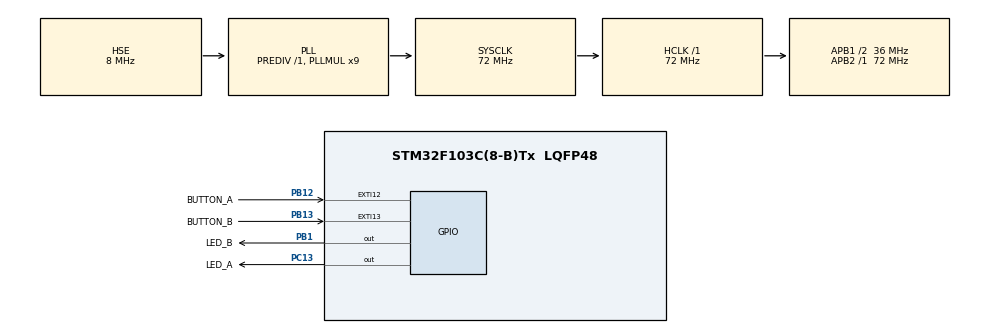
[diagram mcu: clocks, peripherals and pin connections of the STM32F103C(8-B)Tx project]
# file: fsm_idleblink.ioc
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Mcu.Family=STM32F1
RCC.PLLSourceVirtual=RCC_PLLSOURCE_HSE
PC15-OSC32_OUT.Mode=LSE-External-Oscillator
PD1-OSC_OUT.Mode=HSE-External-Oscillator
PC13-TAMPER-RTC.Signal=GPIO_Output
PD0-OSC_IN.Signal=RCC_OSC_IN
RCC.APB1CLKDivider=RCC_HCLK_DIV2
PC14-OSC32_IN.Signal=RCC_OSC32_IN
PB13.GPIO_Label=BUTTON_B
PB13.Signal=GPXTI13
PB13.GPIO_ModeDefaultEXTI=GPIO_MODE_IT_FALLING
RCC.SYSCLKSource=RCC_SYSCLKSOURCE_PLLCLK
ProjectManager.StackSize=0x400
PD1-OSC_OUT.Signal=RCC_OSC_OUT
PA13.Signal=SYS_JTMS-SWDIO
ProjectManager.TargetToolchain=STM32CubeIDE
RCC.HCLKFreq_Value=72000000
RCC.APB2TimFreq_Value=72000000
RCC.USBFreq_Value=72000000
PC15-OSC32_OUT.Signal=RCC_OSC32_OUT
RCC.AHBFreq_Value=72000000
PD0-OSC_IN.Mode=HSE-External-Oscillator
NVIC.EXTI15_10_IRQn=true\:0\:0\:false\:false\:true\:true\:true
board=custom
PC13-TAMPER-RTC.GPIO_Label=LED_A
RCC.PLLMUL=RCC_PLL_MUL9
PB12.GPIO_Label=BUTTON_A
PB13.GPIO_PuPd=GPIO_PULLUP
RCC.APB2Freq_Value=72000000
PC14-OSC32_IN.Mode=LSE-External-Oscillator
PC13-TAMPER-RTC.PinState=GPIO_PIN_SET
PA14.Mode=Serial_Wire
PB1.GPIO_Label=LED_B
PA13.Mode=Serial_Wire
Mcu.Name=STM32F103C(8-B)Tx
PB1.PinState=GPIO_PIN_SET
RCC.SYSCLKFreq_VALUE=72000000
Mcu.Package=LQFP48
PB1.Signal=GPIO_Output
PA14.Signal=SYS_JTCK-SWCLK
ProjectManager.HeapSize=0x200
PB12.GPIO_ModeDefaultEXTI=GPIO_MODE_IT_FALLING
NVIC.PriorityGroup=NVIC_PRIORITYGROUP_4
RCC.APB1TimFreq_Value=72000000
PB12.GPIO_PuPd=GPIO_PULLUP
RCC.APB1Freq_Value=36000000
PB12.Signal=GPXTI12

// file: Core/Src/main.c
/* USER CODE BEGIN Header */
/**
 ******************************************************************************
 * @file           : main.c
 * @brief          : Main program body
 ******************************************************************************
 * @attention
 *
 * <h2><center>&copy; Copyright (c) 2021 STMicroelectronics.
 * All rights reserved.</center></h2>
 *
 * This software component is licensed by ST under BSD 3-Clause license,
 * the "License"; You may not use this file except in compliance with the
 * License. You may obtain a copy of the License at:
 *                        opensource.org/licenses/BSD-3-Clause
 *
 ******************************************************************************
 */
/* USER CODE END Header */
#include "main.h"

/* USER CODE BEGIN Includes */
#include "fsm_idleblink.h"
#include "user_gpio.h"
/* USER CODE END Includes */

void SystemClock_Config(void);
static void MX_GPIO_Init(void);

/* USER CODE BEGIN 0 */

/**
 * @brief  This function is called by the SysTick interrupt handler every
 *         1 ms by default.
 * @note   This implementation overrides the existing weak function in
 *         stm32f1xx_hal.c file.
 * @retval None
 */
void HAL_IncTick(void)
{
	uwTick += uwTickFreq;
	fsm_idleblink_tick();
}

/* USER CODE END 0 */

int main(void)
{

	/* MCU Configuration--------------------------------------------------------*/

	/* Reset of all peripherals, Initializes the Flash interface and the Systick. */
	HAL_Init();

	/* Configure the system clock */
	SystemClock_Config();

	/* Initialize all configured peripherals */
	MX_GPIO_Init();
	/* USER CODE BEGIN 2 */
	user_gpio_init();
	fsm_idleblink_init();
	/* USER CODE END 2 */

	/* Infinite loop */
	/* USER CODE BEGIN WHILE */
	while (1)
	{
		user_gpio_loop();
		fsm_idleblink_loop();

		__WFI();

		/* USER CODE END WHILE */

	}
}

void SystemClock_Config(void)
{
	RCC_OscInitTypeDef RCC_OscInitStruct = {0};
	RCC_ClkInitTypeDef RCC_ClkInitStruct = {0};

	/** Initializes the RCC Oscillators according to the specified parameters
	 * in the RCC_OscInitTypeDef structure.
	 */
	RCC_OscInitStruct.OscillatorType = RCC_OSCILLATORTYPE_HSE;
	RCC_OscInitStruct.HSEState = RCC_HSE_ON;
	RCC_OscInitStruct.HSEPredivValue = RCC_HSE_PREDIV_DIV1;
	RCC_OscInitStruct.HSIState = RCC_HSI_ON;
	RCC_OscInitStruct.PLL.PLLState = RCC_PLL_ON;
	RCC_OscInitStruct.PLL.PLLSource = RCC_PLLSOURCE_HSE;
	RCC_OscInitStruct.PLL.PLLMUL = RCC_PLL_MUL9;
	if (HAL_RCC_OscConfig(&RCC_OscInitStruct) != HAL_OK)
	{
		Error_Handler();
	}
	/** Initializes the CPU, AHB and APB buses clocks
	 */
	RCC_ClkInitStruct.ClockType = RCC_CLOCKTYPE_HCLK|RCC_CLOCKTYPE_SYSCLK
			|RCC_CLOCKTYPE_PCLK1|RCC_CLOCKTYPE_PCLK2;
	RCC_ClkInitStruct.SYSCLKSource = RCC_SYSCLKSOURCE_PLLCLK;
	RCC_ClkInitStruct.AHBCLKDivider = RCC_SYSCLK_DIV1;
	RCC_ClkInitStruct.APB1CLKDivider = RCC_HCLK_DIV2;
	RCC_ClkInitStruct.APB2CLKDivider = RCC_HCLK_DIV1;

	if (HAL_RCC_ClockConfig(&RCC_ClkInitStruct, FLASH_LATENCY_2) != HAL_OK)
	{
		Error_Handler();
	}
}

static void MX_GPIO_Init(void)
{
	GPIO_InitTypeDef GPIO_InitStruct = {0};

	/* GPIO Ports Clock Enable */
	__HAL_RCC_GPIOC_CLK_ENABLE();
	__HAL_RCC_GPIOD_CLK_ENABLE();
	__HAL_RCC_GPIOB_CLK_ENABLE();
	__HAL_RCC_GPIOA_CLK_ENABLE();

	/*Configure GPIO pin Output Level */
	HAL_GPIO_WritePin(LED_A_GPIO_Port, LED_A_Pin, GPIO_PIN_SET);

	/*Configure GPIO pin Output Level */
	HAL_GPIO_WritePin(LED_B_GPIO_Port, LED_B_Pin, GPIO_PIN_SET);

	/*Configure GPIO pin : LED_A_Pin */
	GPIO_InitStruct.Pin = LED_A_Pin;
	GPIO_InitStruct.Mode = GPIO_MODE_OUTPUT_PP;
	GPIO_InitStruct.Pull = GPIO_NOPULL;
	GPIO_InitStruct.Speed = GPIO_SPEED_FREQ_LOW;
	HAL_GPIO_Init(LED_A_GPIO_Port, &GPIO_InitStruct);

	/*Configure GPIO pin : LED_B_Pin */
	GPIO_InitStruct.Pin = LED_B_Pin;
	GPIO_InitStruct.Mode = GPIO_MODE_OUTPUT_PP;
	GPIO_InitStruct.Pull = GPIO_NOPULL;
	GPIO_InitStruct.Speed = GPIO_SPEED_FREQ_LOW;
	HAL_GPIO_Init(LED_B_GPIO_Port, &GPIO_InitStruct);

	/*Configure GPIO pins : BUTTON_A_Pin BUTTON_B_Pin */
	GPIO_InitStruct.Pin = BUTTON_A_Pin|BUTTON_B_Pin;
	GPIO_InitStruct.Mode = GPIO_MODE_IT_FALLING;
	GPIO_InitStruct.Pull = GPIO_PULLUP;
	HAL_GPIO_Init(GPIOB, &GPIO_InitStruct);

	/* EXTI interrupt init*/
	HAL_NVIC_SetPriority(EXTI15_10_IRQn, 0, 0);
	HAL_NVIC_EnableIRQ(EXTI15_10_IRQn);

}

void Error_Handler(void)
{
	__disable_irq();
	while (1)
	{
	}
}

/************************ (C) COPYRIGHT STMicroelectronics *****END OF FILE****/
